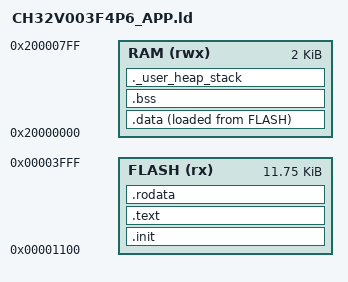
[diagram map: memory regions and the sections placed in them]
/*
 * Auto-generated by mcu-description/tools/generate.py - DO NOT EDIT BY HAND.
 * Source: mcu-description/devices/CH32V003F4P6.yaml
 * Regenerate: python3 mcu-description/tools/generate.py --device CH32V003F4P6
 */

ENTRY(_start)

_Min_Heap_Size  = 0x100;
_Min_Stack_Size = 0x100;

MEMORY
{
  FLASH (rx)  : ORIGIN = 0x00001100, LENGTH = 0x2F00
  RAM   (rwx) : ORIGIN = 0x20000000, LENGTH = 0x800
}

_estack = ORIGIN(RAM) + LENGTH(RAM);

SECTIONS
{
  .init :
  {
    . = ALIGN(4);
    KEEP(*(.init))
    . = ALIGN(4);
  } > FLASH

  .text :
  {
    . = ALIGN(4);
    *(.text)
    *(.text*)
    KEEP (*(.init.rust))
    . = ALIGN(4);
    _etext = .;
  } > FLASH

  .rodata :
  {
    . = ALIGN(4);
    *(.rodata)
    *(.rodata*)
    . = ALIGN(4);
  } > FLASH

  _sidata = LOADADDR(.data);

  .data :
  {
    . = ALIGN(4);
    _sdata = .;
    /* __global_pointer$ - view docstring at the beginning of file (gp-relative addressing, startup.S `la
       gp, __global_pointer$` before .data/.bss is used - must be defined before startup uses me,
       otherwise error link
       "undefined symbol"). */
    PROVIDE(__global_pointer$ = . + 0x800);
    *(.sdata)
    *(.sdata*)
    *(.data)
    *(.data*)
    . = ALIGN(4);
    _edata = .;
  } > RAM AT> FLASH

  . = ALIGN(4);
  .bss :
  {
    _sbss = .;
    *(.sbss)
    *(.sbss*)
    *(.bss)
    *(.bss*)
    *(COMMON)
    . = ALIGN(4);
    _ebss = .;
  } > RAM

  ._user_heap_stack :
  {
    . = ALIGN(8);
    PROVIDE ( end = . );
    PROVIDE ( _end = . );
    . = . + _Min_Heap_Size;
    . = . + _Min_Stack_Size;
    . = ALIGN(8);
  } > RAM

  /* there is no /DISCARD/ libc.a/libm.a/libgcc.a as ARM - riscv64-elf-gcc (Homebrew) compiler is
     optional, does not include newlib (other arm-none-eabi-gcc uses nano.specs/nosys.specs) -
     bare-metal safe build (-nostdlib -ffreestanding), there is no libc.a to discard. */
}
